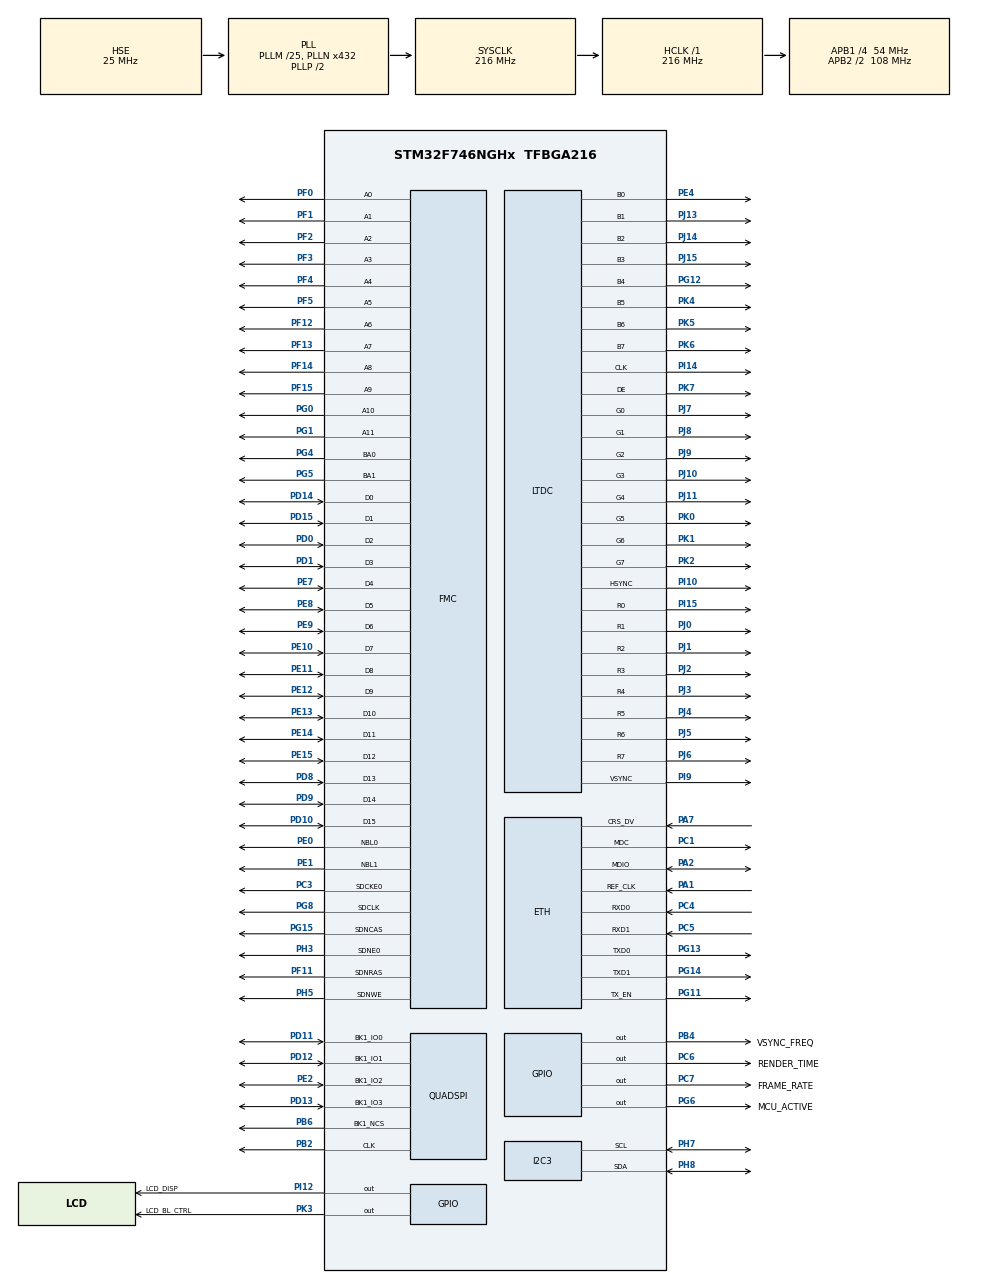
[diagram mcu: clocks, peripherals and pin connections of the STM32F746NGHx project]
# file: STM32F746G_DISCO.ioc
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CORTEX_M7.ART_ACCLERATOR_ENABLE=1
CORTEX_M7.AccessPermission-Cortex_Memory_Protection_Unit_Region0_Settings=MPU_REGION_FULL_ACCESS
CORTEX_M7.AccessPermission-Cortex_Memory_Protection_Unit_Region1_Settings=MPU_REGION_FULL_ACCESS
CORTEX_M7.BaseAddress-Cortex_Memory_Protection_Unit_Region0_Settings=0x2004C000
CORTEX_M7.BaseAddress-Cortex_Memory_Protection_Unit_Region1_Settings=0x90000000
CORTEX_M7.CPU_DCache=Enabled
CORTEX_M7.CPU_ICache=Enabled
CORTEX_M7.Enable-Cortex_Memory_Protection_Unit_Region0_Settings=MPU_REGION_ENABLE
CORTEX_M7.Enable-Cortex_Memory_Protection_Unit_Region1_Settings=MPU_REGION_ENABLE
CORTEX_M7.IsCacheable-Cortex_Memory_Protection_Unit_Region1_Settings=MPU_ACCESS_CACHEABLE
CORTEX_M7.MPU_Control=MPU_HFNMI_PRIVDEF
CORTEX_M7.PREFETCH_ENABLE=1
CORTEX_M7.Size-Cortex_Memory_Protection_Unit_Region0_Settings=MPU_REGION_SIZE_16KB
CORTEX_M7.Size-Cortex_Memory_Protection_Unit_Region1_Settings=MPU_REGION_SIZE_16MB
CORTEX_M7.TypeExtField-Cortex_Memory_Protection_Unit_Region0_Settings=MPU_TEX_LEVEL1
ETH.MediaInterface=HAL_ETH_RMII_MODE
FMC.CASLatency1=FMC_SDRAM_CAS_LATENCY_3
FMC.ExitSelfRefreshDelay1=7
FMC.LoadToActiveDelay1=2
FMC.RCDDelay1=2
FMC.RPDelay1=2
FMC.ReadBurst1=FMC_SDRAM_RBURST_ENABLE
FMC.RowCycleDelay1=7
FMC.SDClockPeriod1=FMC_SDRAM_CLOCK_PERIOD_2
FMC.SelfRefreshTime1=4
FMC.WriteRecoveryTime1=3
FREERTOS.Tasks01=defaultTask,24,1024,StartDefaultTask,Default,NULL,Dynamic,NULL,NULL;TouchGFXTask,24,4096,TouchGFX_Task,As external,NULL,Dynamic,NULL,NULL;videoTask,8,1000,videoTaskFunc,As external,NULL,Dynamic,NULL,NULL;llrpTask,24,1024,StartLlrpTask,As external,NULL,Dynamic,NULL,NULL
FREERTOS.configTOTAL_HEAP_SIZE=65536
FREERTOS.configUSE_APPLICATION_TASK_TAG=1
FREERTOS.configUSE_IDLE_HOOK=1
I2C3.Timing=0x20404768
LIBJPEG.RGB_ORDERING=BGR
LTDC.ActiveH=272
LTDC.ActiveW=480
LTDC.Alpha_L0=255
LTDC.FBStartAdress_L0=0xC0000000
LTDC.HBP=13
LTDC.HFP=32
LTDC.HSync=41
LTDC.ImageHeight_L0=272
LTDC.ImageWidth_L0=480
LTDC.Layers=0
LTDC.PixelFormat_L0=LTDC_PIXEL_FORMAT_RGB565
LTDC.VSync=10
LTDC.WindowX1_L0=480
LTDC.WindowY1_L0=272
LWIP.BSP.number=1
LWIP.GATEWAY_ADDRESS=000.000.000.000
LWIP.IP_ADDRESS=169.254.001.002
LWIP.LWIP_DHCP=0
LWIP.NETMASK_ADDRESS=255.255.000.000
LWIP.Version=v2.1.2_Cube
LWIP0.BSP.STBoard=false
LWIP0.BSP.api=BSP_COMPONENT_DRIVER
LWIP0.BSP.component=LAN8742
LWIP0.BSP.instance=LAN8742
LWIP0.BSP.name=Driver_PHY
LWIP0.BSP.semaphore=S_LAN8742
LWIP0.BSP.solution=LAN8742
Mcu.Family=STM32F7
Mcu.Name=STM32F746NGHx
Mcu.Package=TFBGA216
NVIC.DMA2D_IRQn=true\:5\:0\:true\:false\:true\:true\:true\:true\:true
NVIC.ETH_IRQn=true\:5\:0\:false\:false\:true\:true\:false\:true\:true
NVIC.LTDC_IRQn=true\:5\:0\:true\:false\:true\:true\:true\:true\:true
NVIC.PriorityGroup=NVIC_PRIORITYGROUP_4
NVIC.TIM6_DAC_IRQn=true\:0\:0\:false\:false\:true\:false\:false\:true\:true
NVIC.TimeBase=TIM6_DAC_IRQn
NVIC.TimeBaseIP=TIM6
PA1.Mode=RMII
PA1.Signal=ETH_REF_CLK
PA13.Mode=Serial_Wire
PA13.Signal=SYS_JTMS-SWDIO
PA14.Mode=Serial_Wire
PA14.Signal=SYS_JTCK-SWCLK
PA2.Mode=RMII
PA2.Signal=ETH_MDIO
PA7.Mode=RMII
PA7.Signal=ETH_CRS_DV
PB2.Mode=Single Bank 1
PB2.Signal=QUADSPI_CLK
PB4.GPIO_Label=VSYNC_FREQ
PB4.GPIO_Speed=GPIO_SPEED_FREQ_VERY_HIGH
PB4.Signal=GPIO_Output
PB6.Mode=Single Bank 1
PB6.Signal=QUADSPI_BK1_NCS
PC1.Mode=RMII
PC1.Signal=ETH_MDC
PC3.Mode=SdramChipSelect1_1
PC3.Signal=FMC_SDCKE0
PC4.Mode=RMII
PC4.Signal=ETH_RXD0
PC5.Mode=RMII
PC5.Signal=ETH_RXD1
PC6.GPIO_Label=RENDER_TIME
PC6.GPIO_Speed=GPIO_SPEED_FREQ_VERY_HIGH
PC6.Signal=GPIO_Output
PC7.GPIO_Label=FRAME_RATE
PC7.GPIO_Speed=GPIO_SPEED_FREQ_VERY_HIGH
PC7.Signal=GPIO_Output
PD0.Signal=FMC_D2_DA2
PD1.Signal=FMC_D3_DA3
PD10.Signal=FMC_D15_DA15
PD11.Mode=Single Bank 1
PD11.Signal=QUADSPI_BK1_IO0
PD12.Mode=Single Bank 1
PD12.Signal=QUADSPI_BK1_IO1
PD13.Mode=Single Bank 1
PD13.Signal=QUADSPI_BK1_IO3
PD14.Signal=FMC_D0_DA0
PD15.Signal=FMC_D1_DA1
PD8.Signal=FMC_D13_DA13
PD9.Signal=FMC_D14_DA14
PE0.Signal=FMC_NBL0
PE1.Signal=FMC_NBL1
PE10.Signal=FMC_D7_DA7
PE11.Signal=FMC_D8_DA8
PE12.Signal=FMC_D9_DA9
PE13.Signal=FMC_D10_DA10
PE14.Signal=FMC_D11_DA11
PE15.Signal=FMC_D12_DA12
PE2.Mode=Single Bank 1
PE2.Signal=QUADSPI_BK1_IO2
PE4.Mode=RGB888
PE4.Signal=LTDC_B0
PE7.Signal=FMC_D4_DA4
PE8.Signal=FMC_D5_DA5
PE9.Signal=FMC_D6_DA6
PF0.Signal=FMC_A0
PF1.Signal=FMC_A1
PF11.Signal=FMC_SDNRAS
PF12.Signal=FMC_A6
PF13.Signal=FMC_A7
PF14.Signal=FMC_A8
PF15.Signal=FMC_A9
PF2.Signal=FMC_A2
PF3.Signal=FMC_A3
PF4.Signal=FMC_A4
PF5.Signal=FMC_A5
PG0.Signal=FMC_A10
PG1.Signal=FMC_A11
PG11.Mode=RMII
PG11.Signal=ETH_TX_EN
PG12.Mode=RGB888
PG12.Signal=LTDC_B4
PG13.Mode=RMII
PG13.Signal=ETH_TXD0
PG14.Mode=RMII
PG14.Signal=ETH_TXD1
PG15.Signal=FMC_SDNCAS
PG4.Signal=FMC_A14_BA0
PG5.Signal=FMC_A15_BA1
PG6.GPIO_Label=MCU_ACTIVE
PG6.GPIO_Speed=GPIO_SPEED_FREQ_VERY_HIGH
PG6.Signal=GPIO_Output
PG8.Signal=FMC_SDCLK
PH0/OSC_IN.Mode=HSE-External-Oscillator
PH0/OSC_IN.Signal=RCC_OSC_IN
PH1/OSC_OUT.Mode=HSE-External-Oscillator
PH1/OSC_OUT.Signal=RCC_OSC_OUT
PH3.Mode=SdramChipSelect1_1
PH3.Signal=FMC_SDNE0
PH5.Signal=FMC_SDNWE
PH7.GPIO_Pu=GPIO_PULLUP
PH7.Mode=I2C
PH7.Signal=I2C3_SCL
PH8.GPIO_Pu=GPIO_PULLUP
PH8.Mode=I2C
PH8.Signal=I2C3_SDA
PI10.Mode=RGB888
PI10.Signal=LTDC_HSYNC
PI12.GPIO_Label=LCD_DISP
PI12.PinState=GPIO_PIN_SET
PI12.Signal=GPIO_Output
PI14.Mode=RGB888
PI14.Signal=LTDC_CLK
PI15.Mode=RGB888
PI15.Signal=LTDC_R0
PI9.Mode=RGB888
PI9.Signal=LTDC_VSYNC
PJ0.Mode=RGB888
PJ0.Signal=LTDC_R1
PJ1.Mode=RGB888
PJ1.Signal=LTDC_R2
PJ10.Mode=RGB888
PJ10.Signal=LTDC_G3
PJ11.Mode=RGB888
PJ11.Signal=LTDC_G4
PJ13.Mode=RGB888
PJ13.Signal=LTDC_B1
PJ14.Mode=RGB888
PJ14.Signal=LTDC_B2
PJ15.Mode=RGB888
PJ15.Signal=LTDC_B3
PJ2.Mode=RGB888
PJ2.Signal=LTDC_R3
PJ3.Mode=RGB888
PJ3.Signal=LTDC_R4
PJ4.Mode=RGB888
PJ4.Signal=LTDC_R5
PJ5.Mode=RGB888
PJ5.Signal=LTDC_R6
PJ6.Mode=RGB888
PJ6.Signal=LTDC_R7
PJ7.Mode=RGB888
PJ7.Signal=LTDC_G0
PJ8.Mode=RGB888
PJ8.Signal=LTDC_G1
PJ9.Mode=RGB888
PJ9.Signal=LTDC_G2
PK0.Mode=RGB888
PK0.Signal=LTDC_G5
PK1.Mode=RGB888
PK1.Signal=LTDC_G6
PK2.Mode=RGB888
PK2.Signal=LTDC_G7
PK3.GPIO_Label=LCD_BL_CTRL
PK3.PinState=GPIO_PIN_SET
PK3.Signal=GPIO_Output
PK4.Mode=RGB888
PK4.Signal=LTDC_B5
PK5.Mode=RGB888
PK5.Signal=LTDC_B6
PK6.Mode=RGB888
PK6.Signal=LTDC_B7
PK7.Mode=RGB888
PK7.Signal=LTDC_DE
ProjectManager.HeapSize=0xA00
ProjectManager.StackSize=0xA00
ProjectManager.TargetToolchain=STM32CubeIDE
QUADSPI.ChipSelectHighTime=QSPI_CS_HIGH_TIME_6_CYCLE
QUADSPI.ClockPrescaler=1
QUADSPI.FifoThreshold=4
QUADSPI.FlashSize=24
QUADSPI.SampleShifting=QSPI_SAMPLE_SHIFTING_HALFCYCLE
RCC.AHBFreq_Value=216000000
RCC.APB1CLKDivider=RCC_HCLK_DIV4
RCC.APB1Freq_Value=54000000
RCC.APB1TimFreq_Value=108000000
RCC.APB2CLKDivider=RCC_HCLK_DIV2
RCC.APB2Freq_Value=108000000
RCC.APB2TimFreq_Value=216000000
RCC.CortexFreq_Value=216000000
RCC.HCLKFreq_Value=216000000
RCC.HSE_VALUE=25000000
RCC.HSI_VALUE=16000000
RCC.LSE_VALUE=32768
RCC.PLLI2SN=100
RCC.PLLM=25
RCC.PLLN=432
RCC.PLLSAIN=384
RCC.PLLSAIR=5
RCC.PLLSAIRDiv=RCC_PLLSAIDIVR_8
RCC.PLLSourceVirtual=RCC_PLLSOURCE_HSE
RCC.SYSCLKFreq_VALUE=216000000
RCC.SYSCLKSource=RCC_SYSCLKSOURCE_PLLCLK
RCC.USBFreq_Value=216000000
RCC.VCOOutputFreq_Value=432000000
SH.FMC_A0.0=FMC_A0,12b-sda1
SH.FMC_A1.0=FMC_A1,12b-sda1
SH.FMC_A10.0=FMC_A10,12b-sda1
SH.FMC_A11.0=FMC_A11,12b-sda1
SH.FMC_A14_BA0.0=FMC_BA0,FourSdramBanks1
SH.FMC_A15_BA1.0=FMC_BA1,FourSdramBanks1
SH.FMC_A2.0=FMC_A2,12b-sda1
SH.FMC_A3.0=FMC_A3,12b-sda1
SH.FMC_A4.0=FMC_A4,12b-sda1
SH.FMC_A5.0=FMC_A5,12b-sda1
SH.FMC_A6.0=FMC_A6,12b-sda1
SH.FMC_A7.0=FMC_A7,12b-sda1
SH.FMC_A8.0=FMC_A8,12b-sda1
SH.FMC_A9.0=FMC_A9,12b-sda1
SH.FMC_D0_DA0.0=FMC_D0,sd-16b-d1
SH.FMC_D10_DA10.0=FMC_D10,sd-16b-d1
SH.FMC_D11_DA11.0=FMC_D11,sd-16b-d1
SH.FMC_D12_DA12.0=FMC_D12,sd-16b-d1
SH.FMC_D13_DA13.0=FMC_D13,sd-16b-d1
SH.FMC_D14_DA14.0=FMC_D14,sd-16b-d1
SH.FMC_D15_DA15.0=FMC_D15,sd-16b-d1
SH.FMC_D1_DA1.0=FMC_D1,sd-16b-d1
SH.FMC_D2_DA2.0=FMC_D2,sd-16b-d1
SH.FMC_D3_DA3.0=FMC_D3,sd-16b-d1
SH.FMC_D4_DA4.0=FMC_D4,sd-16b-d1
SH.FMC_D5_DA5.0=FMC_D5,sd-16b-d1
SH.FMC_D6_DA6.0=FMC_D6,sd-16b-d1
SH.FMC_D7_DA7.0=FMC_D7,sd-16b-d1
SH.FMC_D8_DA8.0=FMC_D8,sd-16b-d1
SH.FMC_D9_DA9.0=FMC_D9,sd-16b-d1
SH.FMC_NBL0.0=FMC_NBL0,Sd2ByteEnable1
SH.FMC_NBL1.0=FMC_NBL1,Sd2ByteEnable1
SH.FMC_SDCLK.0=FMC_SDCLK,12b-sda1
SH.FMC_SDNCAS.0=FMC_SDNCAS,12b-sda1
SH.FMC_SDNRAS.0=FMC_SDNRAS,12b-sda1
SH.FMC_SDNWE.0=FMC_SDNWE,12b-sda1
STMicroelectronics.X-CUBE-TOUCHGFX.4.26.0.ApplicationCcGraphicsJjApplication=TouchGFXOoGenerator
STMicroelectronics.X-CUBE-TOUCHGFX.4.26.0.tgfx_address1=0xC0000000
STMicroelectronics.X-CUBE-TOUCHGFX.4.26.0.tgfx_address2=0xC003FC00
STMicroelectronics.X-CUBE-TOUCHGFX.4.26.0.tgfx_buffering_strategy=Double
STMicroelectronics.X-CUBE-TOUCHGFX.4.26.0.tgfx_display_interface=disp_ltdc
STMicroelectronics.X-CUBE-TOUCHGFX.4.26.0.tgfx_hardware_accelerator=dma_2d
STMicroelectronics.X-CUBE-TOUCHGFX.4.26.0.tgfx_location=Allocate
STMicroelectronics.X-CUBE-TOUCHGFX.4.26.0.tgfx_vector_fonts=Enabled
STMicroelectronics.X-CUBE-TOUCHGFX.4.26.0.tgfx_vector_rendering=Software
STMicroelectronics.X-CUBE-TOUCHGFX.4.26.0.tgfx_video=Software
STMicroelectronics.X-CUBE-TOUCHGFX.4.26.0.tgfx_video_buffer_format=RGB565\:2
STMicroelectronics.X-CUBE-TOUCHGFX.4.26.0.tgfx_video_height=272
STMicroelectronics.X-CUBE-TOUCHGFX.4.26.0.tgfx_video_strategy=2
STMicroelectronics.X-CUBE-TOUCHGFX.4.26.0.tgfx_video_width=480
STMicroelectronics.X-CUBE-TOUCHGFX.4.26.0.tgfx_vsync=vsync_ltdc
VP_CRC_VS_CRC.Mode=CRC_Activate
VP_DMA2D_VS_DMA2D.Mode=DMA2D_Activate
VP_FREERTOS_VS_CMSIS_V2.Mode=CMSIS_V2
VP_LIBJPEG_VS_JPEGLIB.Mode=Enabled
VP_LWIP_VS_Enabled.Mode=Enabled
VP_STMicroelectronics.X-CUBE-TOUCHGFX_VS_GraphicsJjApplication_4.26.0.Mode=GraphicsJjApplication
VP_SYS_VS_tim6.Mode=TIM6
board=custom

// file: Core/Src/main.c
/* USER CODE BEGIN Header */
/**
 ******************************************************************************
 * @file           : main.c
 * @brief          : Main program body
 ******************************************************************************
 * @attention
 *
 * <h2><center>&copy; Copyright (c) 2020 STMicroelectronics.
 * All rights reserved.</center></h2>
 *
 * This software component is licensed by ST under Ultimate Liberty license
 * SLA0044, the "License"; You may not use this file except in compliance with
 * the License. You may obtain a copy of the License at:
 *                             www.st.com/SLA0044
 *
 ******************************************************************************
 */
/* USER CODE END Header */
#include "main.h"
#include "app_touchgfx.h"
#include "cmsis_os.h"
#include "libjpeg.h"
#include "lwip.h"

/* USER CODE BEGIN PD */

#define REFRESH_COUNT 1835

#define SDRAM_TIMEOUT ((uint32_t)0xFFFF)
#define SDRAM_MODEREG_BURST_LENGTH_1 ((uint16_t)0x0000)
#define SDRAM_MODEREG_BURST_LENGTH_2 ((uint16_t)0x0001)
#define SDRAM_MODEREG_BURST_LENGTH_4 ((uint16_t)0x0002)
#define SDRAM_MODEREG_BURST_LENGTH_8 ((uint16_t)0x0004)
#define SDRAM_MODEREG_BURST_TYPE_SEQUENTIAL ((uint16_t)0x0000)
#define SDRAM_MODEREG_BURST_TYPE_INTERLEAVED ((uint16_t)0x0008)
#define SDRAM_MODEREG_CAS_LATENCY_2 ((uint16_t)0x0020)
#define SDRAM_MODEREG_CAS_LATENCY_3 ((uint16_t)0x0030)
#define SDRAM_MODEREG_OPERATING_MODE_STANDARD ((uint16_t)0x0000)
#define SDRAM_MODEREG_WRITEBURST_MODE_PROGRAMMED ((uint16_t)0x0000)
#define SDRAM_MODEREG_WRITEBURST_MODE_SINGLE ((uint16_t)0x0200)

#define FLASH_READ_JEDEC_ID 0x9F
#define FLASH_FAST_READ_QUAD_IO 0xEB
#define FLASH_REVC03_MANUFACTURER_ID 0xEF
#define FLASH_N25Q128A_DUMMY_CYCLES 0x0A
#define FLASH_W25Q128J_DUMMY_CYCLES 0x06

/* USER CODE END PD */

CRC_HandleTypeDef hcrc;

DMA2D_HandleTypeDef hdma2d;

I2C_HandleTypeDef hi2c3;

LTDC_HandleTypeDef hltdc;

QSPI_HandleTypeDef hqspi;

SDRAM_HandleTypeDef hsdram1;

/* Definitions for defaultTask */
osThreadId_t defaultTaskHandle;
const osThreadAttr_t defaultTask_attributes = {
    .name = "defaultTask",
    .stack_size = 1024 * 4,
    .priority = (osPriority_t)osPriorityNormal,
};
/* Definitions for TouchGFXTask */
osThreadId_t TouchGFXTaskHandle;
const osThreadAttr_t TouchGFXTask_attributes = {
    .name = "TouchGFXTask",
    .stack_size = 4096 * 4,
    .priority = (osPriority_t)osPriorityNormal,
};
/* Definitions for videoTask */
osThreadId_t videoTaskHandle;
const osThreadAttr_t videoTask_attributes = {
    .name = "videoTask",
    .stack_size = 1000 * 4,
    .priority = (osPriority_t)osPriorityLow,
};
/* Definitions for llrpTask */
osThreadId_t llrpTaskHandle;
const osThreadAttr_t llrpTask_attributes = {
    .name = "llrpTask",
    .stack_size = 1024 * 4,
    .priority = (osPriority_t)osPriorityNormal,
};
/* USER CODE BEGIN PV */
static FMC_SDRAM_CommandTypeDef Command;
/* USER CODE END PV */

void SystemClock_Config(void);
static void MPU_Config(void);
static void MX_GPIO_Init(void);
static void MX_CRC_Init(void);
static void MX_DMA2D_Init(void);
static void MX_FMC_Init(void);
static void MX_I2C3_Init(void);
static void MX_LTDC_Init(void);
static void MX_QUADSPI_Init(void);
void StartDefaultTask(void *argument);
extern void TouchGFX_Task(void *argument);
extern void videoTaskFunc(void *argument);
extern void StartLlrpTask(void *argument);

/* USER CODE BEGIN PFP */
void GetManufacturerId(uint8_t *manufacturer_id);
void EnableMemoryMappedMode(uint8_t manufacturer_id);
extern void StartLlrpTask(void *argument);
/* USER CODE END PFP */

int main(void) {

  /* MPU Configuration--------------------------------------------------------*/
  MPU_Config();

  /* Enable the CPU Cache */

  /* Enable I-Cache---------------------------------------------------------*/
  SCB_EnableICache();

  /* Enable D-Cache---------------------------------------------------------*/
  SCB_EnableDCache();

  /* MCU Configuration--------------------------------------------------------*/

  /* Reset of all peripherals, Initializes the Flash interface and the Systick.
   */
  HAL_Init();

  /* Configure the system clock */
  SystemClock_Config();

  /* Initialize all configured peripherals */
  MX_GPIO_Init();
  MX_CRC_Init();
  MX_DMA2D_Init();
  MX_FMC_Init();
  MX_I2C3_Init();
  MX_LTDC_Init();
  MX_QUADSPI_Init();
  MX_LIBJPEG_Init();
  MX_TouchGFX_Init();
  /* Call PreOsInit function */
  MX_TouchGFX_PreOSInit();

  /* Init scheduler */
  osKernelInitialize();

  /* Create the thread(s) */
  /* creation of defaultTask */
  defaultTaskHandle =
      osThreadNew(StartDefaultTask, NULL, &defaultTask_attributes);

  /* creation of TouchGFXTask */
  TouchGFXTaskHandle =
      osThreadNew(TouchGFX_Task, NULL, &TouchGFXTask_attributes);

  /* creation of videoTask */
  videoTaskHandle = osThreadNew(videoTaskFunc, NULL, &videoTask_attributes);

  /* creation of llrpTask */
  llrpTaskHandle = osThreadNew(StartLlrpTask, NULL, &llrpTask_attributes);

  /* Start scheduler */
  osKernelStart();

  /* We should never get here as control is now taken by the scheduler */

  /* Infinite loop */
  while (1) {

  }
}

void SystemClock_Config(void) {
  RCC_OscInitTypeDef RCC_OscInitStruct = {0};
  RCC_ClkInitTypeDef RCC_ClkInitStruct = {0};

  /** Configure the main internal regulator output voltage
   */
  __HAL_RCC_PWR_CLK_ENABLE();
  __HAL_PWR_VOLTAGESCALING_CONFIG(PWR_REGULATOR_VOLTAGE_SCALE1);

  /** Initializes the RCC Oscillators according to the specified parameters
   * in the RCC_OscInitTypeDef structure.
   */
  RCC_OscInitStruct.OscillatorType = RCC_OSCILLATORTYPE_HSE;
  RCC_OscInitStruct.HSEState = RCC_HSE_ON;
  RCC_OscInitStruct.PLL.PLLState = RCC_PLL_ON;
  RCC_OscInitStruct.PLL.PLLSource = RCC_PLLSOURCE_HSE;
  RCC_OscInitStruct.PLL.PLLM = 25;
  RCC_OscInitStruct.PLL.PLLN = 432;
  RCC_OscInitStruct.PLL.PLLP = RCC_PLLP_DIV2;
  RCC_OscInitStruct.PLL.PLLQ = 2;
  if (HAL_RCC_OscConfig(&RCC_OscInitStruct) != HAL_OK) {
    Error_Handler();
  }

  /** Activate the Over-Drive mode
   */
  if (HAL_PWREx_EnableOverDrive() != HAL_OK) {
    Error_Handler();
  }

  /** Initializes the CPU, AHB and APB buses clocks
   */
  RCC_ClkInitStruct.ClockType = RCC_CLOCKTYPE_HCLK | RCC_CLOCKTYPE_SYSCLK |
                                RCC_CLOCKTYPE_PCLK1 | RCC_CLOCKTYPE_PCLK2;
  RCC_ClkInitStruct.SYSCLKSource = RCC_SYSCLKSOURCE_PLLCLK;
  RCC_ClkInitStruct.AHBCLKDivider = RCC_SYSCLK_DIV1;
  RCC_ClkInitStruct.APB1CLKDivider = RCC_HCLK_DIV4;
  RCC_ClkInitStruct.APB2CLKDivider = RCC_HCLK_DIV2;

  if (HAL_RCC_ClockConfig(&RCC_ClkInitStruct, FLASH_LATENCY_7) != HAL_OK) {
    Error_Handler();
  }
}

static void MX_CRC_Init(void) {

  hcrc.Instance = CRC;
  hcrc.Init.DefaultPolynomialUse = DEFAULT_POLYNOMIAL_ENABLE;
  hcrc.Init.DefaultInitValueUse = DEFAULT_INIT_VALUE_ENABLE;
  hcrc.Init.InputDataInversionMode = CRC_INPUTDATA_INVERSION_NONE;
  hcrc.Init.OutputDataInversionMode = CRC_OUTPUTDATA_INVERSION_DISABLE;
  hcrc.InputDataFormat = CRC_INPUTDATA_FORMAT_BYTES;
  if (HAL_CRC_Init(&hcrc) != HAL_OK) {
    Error_Handler();
  }
}

static void MX_DMA2D_Init(void) {

  hdma2d.Instance = DMA2D;
  hdma2d.Init.Mode = DMA2D_M2M;
  hdma2d.Init.ColorMode = DMA2D_OUTPUT_ARGB8888;
  hdma2d.Init.OutputOffset = 0;
  hdma2d.LayerCfg[1].InputOffset = 0;
  hdma2d.LayerCfg[1].InputColorMode = DMA2D_INPUT_ARGB8888;
  hdma2d.LayerCfg[1].AlphaMode = DMA2D_NO_MODIF_ALPHA;
  hdma2d.LayerCfg[1].InputAlpha = 0;
  if (HAL_DMA2D_Init(&hdma2d) != HAL_OK) {
    Error_Handler();
  }
  if (HAL_DMA2D_ConfigLayer(&hdma2d, 1) != HAL_OK) {
    Error_Handler();
  }
}

static void MX_I2C3_Init(void) {

  /* USER CODE BEGIN I2C3_Init 0 */
  HAL_Delay(100); // Delay to fix initialization issue on some boards
  /* USER CODE END I2C3_Init 0 */

  hi2c3.Instance = I2C3;
  hi2c3.Init.Timing = 0x20404768;
  hi2c3.Init.OwnAddress1 = 0;
  hi2c3.Init.AddressingMode = I2C_ADDRESSINGMODE_7BIT;
  hi2c3.Init.DualAddressMode = I2C_DUALADDRESS_DISABLE;
  hi2c3.Init.OwnAddress2 = 0;
  hi2c3.Init.OwnAddress2Masks = I2C_OA2_NOMASK;
  hi2c3.Init.GeneralCallMode = I2C_GENERALCALL_DISABLE;
  hi2c3.Init.NoStretchMode = I2C_NOSTRETCH_DISABLE;
  if (HAL_I2C_Init(&hi2c3) != HAL_OK) {
    Error_Handler();
  }

  /** Configure Analogue filter
   */
  if (HAL_I2CEx_ConfigAnalogFilter(&hi2c3, I2C_ANALOGFILTER_ENABLE) != HAL_OK) {
    Error_Handler();
  }

  /** Configure Digital filter
   */
  if (HAL_I2CEx_ConfigDigitalFilter(&hi2c3, 0) != HAL_OK) {
    Error_Handler();
  }
}

static void MX_LTDC_Init(void) {

  LTDC_LayerCfgTypeDef pLayerCfg = {0};

  hltdc.Instance = LTDC;
  hltdc.Init.HSPolarity = LTDC_HSPOLARITY_AL;
  hltdc.Init.VSPolarity = LTDC_VSPOLARITY_AL;
  hltdc.Init.DEPolarity = LTDC_DEPOLARITY_AL;
  hltdc.Init.PCPolarity = LTDC_PCPOLARITY_IPC;
  hltdc.Init.HorizontalSync = 40;
  hltdc.Init.VerticalSync = 9;
  hltdc.Init.AccumulatedHBP = 53;
  hltdc.Init.AccumulatedVBP = 11;
  hltdc.Init.AccumulatedActiveW = 533;
  hltdc.Init.AccumulatedActiveH = 283;
  hltdc.Init.TotalWidth = 565;
  hltdc.Init.TotalHeigh = 285;
  hltdc.Init.Backcolor.Blue = 0;
  hltdc.Init.Backcolor.Green = 0;
  hltdc.Init.Backcolor.Red = 0;
  if (HAL_LTDC_Init(&hltdc) != HAL_OK) {
    Error_Handler();
  }
  pLayerCfg.WindowX0 = 0;
  pLayerCfg.WindowX1 = 480;
  pLayerCfg.WindowY0 = 0;
  pLayerCfg.WindowY1 = 272;
  pLayerCfg.PixelFormat = LTDC_PIXEL_FORMAT_RGB565;
  pLayerCfg.Alpha = 255;
  pLayerCfg.Alpha0 = 0;
  pLayerCfg.BlendingFactor1 = LTDC_BLENDING_FACTOR1_CA;
  pLayerCfg.BlendingFactor2 = LTDC_BLENDING_FACTOR2_CA;
  pLayerCfg.FBStartAdress = 0xC0000000;
  pLayerCfg.ImageWidth = 480;
  pLayerCfg.ImageHeight = 272;
  pLayerCfg.Backcolor.Blue = 0;
  pLayerCfg.Backcolor.Green = 0;
  pLayerCfg.Backcolor.Red = 0;
  if (HAL_LTDC_ConfigLayer(&hltdc, &pLayerCfg, 0) != HAL_OK) {
    Error_Handler();
  }
}

static void MX_QUADSPI_Init(void) {

  /* QUADSPI parameter configuration*/
  hqspi.Instance = QUADSPI;
  hqspi.Init.ClockPrescaler = 1;
  hqspi.Init.FifoThreshold = 4;
  hqspi.Init.SampleShifting = QSPI_SAMPLE_SHIFTING_HALFCYCLE;
  hqspi.Init.FlashSize = 24;
  hqspi.Init.ChipSelectHighTime = QSPI_CS_HIGH_TIME_6_CYCLE;
  hqspi.Init.ClockMode = QSPI_CLOCK_MODE_0;
  hqspi.Init.FlashID = QSPI_FLASH_ID_1;
  hqspi.Init.DualFlash = QSPI_DUALFLASH_DISABLE;
  if (HAL_QSPI_Init(&hqspi) != HAL_OK) {
    Error_Handler();
  }
  /* USER CODE BEGIN QUADSPI_Init 2 */
  uint8_t manufacturer_id;
  GetManufacturerId(&manufacturer_id);
  EnableMemoryMappedMode(manufacturer_id);
  HAL_NVIC_DisableIRQ(QUADSPI_IRQn);
  /* USER CODE END QUADSPI_Init 2 */
}

/* FMC initialization function */
static void MX_FMC_Init(void) {

  FMC_SDRAM_TimingTypeDef SdramTiming = {0};

  /** Perform the SDRAM1 memory initialization sequence
   */
  hsdram1.Instance = FMC_SDRAM_DEVICE;
  /* hsdram1.Init */
  hsdram1.Init.SDBank = FMC_SDRAM_BANK1;
  hsdram1.Init.ColumnBitsNumber = FMC_SDRAM_COLUMN_BITS_NUM_8;
  hsdram1.Init.RowBitsNumber = FMC_SDRAM_ROW_BITS_NUM_12;
  hsdram1.Init.MemoryDataWidth = FMC_SDRAM_MEM_BUS_WIDTH_16;
  hsdram1.Init.InternalBankNumber = FMC_SDRAM_INTERN_BANKS_NUM_4;
  hsdram1.Init.CASLatency = FMC_SDRAM_CAS_LATENCY_3;
  hsdram1.Init.WriteProtection = FMC_SDRAM_WRITE_PROTECTION_DISABLE;
  hsdram1.Init.SDClockPeriod = FMC_SDRAM_CLOCK_PERIOD_2;
  hsdram1.Init.ReadBurst = FMC_SDRAM_RBURST_ENABLE;
  hsdram1.Init.ReadPipeDelay = FMC_SDRAM_RPIPE_DELAY_0;
  /* SdramTiming */
  SdramTiming.LoadToActiveDelay = 2;
  SdramTiming.ExitSelfRefreshDelay = 7;
  SdramTiming.SelfRefreshTime = 4;
  SdramTiming.RowCycleDelay = 7;
  SdramTiming.WriteRecoveryTime = 3;
  SdramTiming.RPDelay = 2;
  SdramTiming.RCDDelay = 2;

  if (HAL_SDRAM_Init(&hsdram1, &SdramTiming) != HAL_OK) {
    Error_Handler();
  }

  /* USER CODE BEGIN FMC_Init 2 */
  __IO uint32_t tmpmrd = 0;

  /* Step 1: Configure a clock configuration enable command */
  Command.CommandMode = FMC_SDRAM_CMD_CLK_ENABLE;
  Command.CommandTarget = FMC_SDRAM_CMD_TARGET_BANK1;
  Command.AutoRefreshNumber = 1;
  Command.ModeRegisterDefinition = 0;

  /* Send the command */
  HAL_SDRAM_SendCommand(&hsdram1, &Command, SDRAM_TIMEOUT);

  /* Step 2: Insert 100 us minimum delay */
  /* Inserted delay is equal to 1 ms due to systick time base unit (ms) */
  HAL_Delay(1);

  /* Step 3: Configure a PALL (precharge all) command */
  Command.CommandMode = FMC_SDRAM_CMD_PALL;
  Command.CommandTarget = FMC_SDRAM_CMD_TARGET_BANK1;
  Command.AutoRefreshNumber = 1;
  Command.ModeRegisterDefinition = 0;

  /* Send the command */
  HAL_SDRAM_SendCommand(&hsdram1, &Command, SDRAM_TIMEOUT);

  /* Step 4: Configure an Auto Refresh command */
  Command.CommandMode = FMC_SDRAM_CMD_AUTOREFRESH_MODE;
  Command.CommandTarget = FMC_SDRAM_CMD_TARGET_BANK1;
  Command.AutoRefreshNumber = 8;
  Command.ModeRegisterDefinition = 0;

  /* Send the command */
  HAL_SDRAM_SendCommand(&hsdram1, &Command, SDRAM_TIMEOUT);

  /* Step 5: Program the external memory mode register */
  tmpmrd = (uint32_t)SDRAM_MODEREG_BURST_LENGTH_1 |
           SDRAM_MODEREG_BURST_TYPE_SEQUENTIAL | SDRAM_MODEREG_CAS_LATENCY_3 |
           SDRAM_MODEREG_OPERATING_MODE_STANDARD |
           SDRAM_MODEREG_WRITEBURST_MODE_SINGLE;

  Command.CommandMode = FMC_SDRAM_CMD_LOAD_MODE;
  Command.CommandTarget = FMC_SDRAM_CMD_TARGET_BANK1;
  Command.AutoRefreshNumber = 1;
  Command.ModeRegisterDefinition = tmpmrd;

  /* Send the command */
  HAL_SDRAM_SendCommand(&hsdram1, &Command, SDRAM_TIMEOUT);

  /* Step 6: Set the refresh rate counter */
  /* Set the device refresh rate */
  HAL_SDRAM_ProgramRefreshRate(&hsdram1, REFRESH_COUNT);

  // Deactivate speculative/cache access to first FMC Bank to save FMC bandwidth
  FMC_Bank1->BTCR[0] = 0x000030D2;
  /* USER CODE END FMC_Init 2 */
}

static void MX_GPIO_Init(void) {
  GPIO_InitTypeDef GPIO_InitStruct = {0};

  /* GPIO Ports Clock Enable */
  __HAL_RCC_GPIOE_CLK_ENABLE();
  __HAL_RCC_GPIOG_CLK_ENABLE();
  __HAL_RCC_GPIOB_CLK_ENABLE();
  __HAL_RCC_GPIOA_CLK_ENABLE();
  __HAL_RCC_GPIOJ_CLK_ENABLE();
  __HAL_RCC_GPIOD_CLK_ENABLE();
  __HAL_RCC_GPIOK_CLK_ENABLE();
  __HAL_RCC_GPIOF_CLK_ENABLE();
  __HAL_RCC_GPIOI_CLK_ENABLE();
  __HAL_RCC_GPIOH_CLK_ENABLE();
  __HAL_RCC_GPIOC_CLK_ENABLE();

  /*Configure GPIO pin Output Level */
  HAL_GPIO_WritePin(VSYNC_FREQ_GPIO_Port, VSYNC_FREQ_Pin, GPIO_PIN_RESET);

  /*Configure GPIO pin Output Level */
  HAL_GPIO_WritePin(LCD_BL_CTRL_GPIO_Port, LCD_BL_CTRL_Pin, GPIO_PIN_SET);

  /*Configure GPIO pin Output Level */
  HAL_GPIO_WritePin(LCD_DISP_GPIO_Port, LCD_DISP_Pin, GPIO_PIN_SET);

  /*Configure GPIO pin Output Level */
  HAL_GPIO_WritePin(GPIOC, FRAME_RATE_Pin | RENDER_TIME_Pin, GPIO_PIN_RESET);

  /*Configure GPIO pin Output Level */
  HAL_GPIO_WritePin(MCU_ACTIVE_GPIO_Port, MCU_ACTIVE_Pin, GPIO_PIN_RESET);

  /*Configure GPIO pin : VSYNC_FREQ_Pin */
  GPIO_InitStruct.Pin = VSYNC_FREQ_Pin;
  GPIO_InitStruct.Mode = GPIO_MODE_OUTPUT_PP;
  GPIO_InitStruct.Pull = GPIO_NOPULL;
  GPIO_InitStruct.Speed = GPIO_SPEED_FREQ_VERY_HIGH;
  HAL_GPIO_Init(VSYNC_FREQ_GPIO_Port, &GPIO_InitStruct);

  /*Configure GPIO pin : LCD_BL_CTRL_Pin */
  GPIO_InitStruct.Pin = LCD_BL_CTRL_Pin;
  GPIO_InitStruct.Mode = GPIO_MODE_OUTPUT_PP;
  GPIO_InitStruct.Pull = GPIO_NOPULL;
  GPIO_InitStruct.Speed = GPIO_SPEED_FREQ_LOW;
  HAL_GPIO_Init(LCD_BL_CTRL_GPIO_Port, &GPIO_InitStruct);

  /*Configure GPIO pin : LCD_DISP_Pin */
  GPIO_InitStruct.Pin = LCD_DISP_Pin;
  GPIO_InitStruct.Mode = GPIO_MODE_OUTPUT_PP;
  GPIO_InitStruct.Pull = GPIO_NOPULL;
  GPIO_InitStruct.Speed = GPIO_SPEED_FREQ_LOW;
  HAL_GPIO_Init(LCD_DISP_GPIO_Port, &GPIO_InitStruct);

  /*Configure GPIO pins : FRAME_RATE_Pin RENDER_TIME_Pin */
  GPIO_InitStruct.Pin = FRAME_RATE_Pin | RENDER_TIME_Pin;
  GPIO_InitStruct.Mode = GPIO_MODE_OUTPUT_PP;
  GPIO_InitStruct.Pull = GPIO_NOPULL;
  GPIO_InitStruct.Speed = GPIO_SPEED_FREQ_VERY_HIGH;
  HAL_GPIO_Init(GPIOC, &GPIO_InitStruct);

  /*Configure GPIO pin : MCU_ACTIVE_Pin */
  GPIO_InitStruct.Pin = MCU_ACTIVE_Pin;
  GPIO_InitStruct.Mode = GPIO_MODE_OUTPUT_PP;
  GPIO_InitStruct.Pull = GPIO_NOPULL;
  GPIO_InitStruct.Speed = GPIO_SPEED_FREQ_VERY_HIGH;
  HAL_GPIO_Init(MCU_ACTIVE_GPIO_Port, &GPIO_InitStruct);

}

/* USER CODE BEGIN 4 */

// Read manufacturer ID of external QSPI flash
void GetManufacturerId(uint8_t *manufacturer_id) {
  QSPI_CommandTypeDef s_command_id;

  /* Initialize the read flag status register command */
  s_command_id.InstructionMode = QSPI_INSTRUCTION_1_LINE;
  s_command_id.Instruction = FLASH_READ_JEDEC_ID;
  s_command_id.AddressMode = QSPI_ADDRESS_NONE;
  s_command_id.AlternateByteMode = QSPI_ALTERNATE_BYTES_NONE;
  s_command_id.DataMode = QSPI_DATA_1_LINE;
  s_command_id.DummyCycles = 0;
  s_command_id.NbData = 1;
  s_command_id.DdrMode = QSPI_DDR_MODE_DISABLE;
  s_command_id.DdrHoldHalfCycle = QSPI_DDR_HHC_ANALOG_DELAY;
  s_command_id.SIOOMode = QSPI_SIOO_INST_EVERY_CMD;

  /* Configure the command */
  if (HAL_QSPI_Command(&hqspi, &s_command_id, HAL_QPSI_TIMEOUT_DEFAULT_VALUE) !=
      HAL_OK) {
    Error_Handler();
  }

  /* Reception of the data */
  if (HAL_QSPI_Receive(&hqspi, manufacturer_id,
                       HAL_QPSI_TIMEOUT_DEFAULT_VALUE) != HAL_OK) {
    Error_Handler();
  }
}

// Enable memory mapped mode for external QSPI flash
void EnableMemoryMappedMode(uint8_t manufacturer_id) {
  QSPI_CommandTypeDef s_command;
  QSPI_MemoryMappedTypeDef s_mem_mapped_cfg;

  /* Configure the command for the read instruction */
  s_command.InstructionMode = QSPI_INSTRUCTION_1_LINE;
  s_command.Instruction = FLASH_FAST_READ_QUAD_IO;
  s_command.AddressMode = QSPI_ADDRESS_4_LINES;
  s_command.AddressSize = QSPI_ADDRESS_24_BITS;
  s_command.AlternateByteMode = QSPI_ALTERNATE_BYTES_NONE;
  s_command.DataMode = QSPI_DATA_4_LINES;

  // Set dummy cycles according to manufacturer ID
  s_command.DummyCycles = manufacturer_id == FLASH_REVC03_MANUFACTURER_ID
                              ? FLASH_W25Q128J_DUMMY_CYCLES
                              : FLASH_N25Q128A_DUMMY_CYCLES;

  s_command.DdrMode = QSPI_DDR_MODE_DISABLE;
  s_command.DdrHoldHalfCycle = QSPI_DDR_HHC_ANALOG_DELAY;
  s_command.SIOOMode = QSPI_SIOO_INST_EVERY_CMD;

  /* Configure the memory mapped mode */
  s_mem_mapped_cfg.TimeOutActivation = QSPI_TIMEOUT_COUNTER_DISABLE;
  s_mem_mapped_cfg.TimeOutPeriod = 0;

  if (HAL_QSPI_MemoryMapped(&hqspi, &s_command, &s_mem_mapped_cfg) != HAL_OK) {
    Error_Handler();
  }
}

/* USER CODE END 4 */

/* USER CODE BEGIN Header_StartDefaultTask */
/**
 * @brief  Function implementing the defaultTask thread.
 * @param  argument: Not used
 * @retval None
 */
extern struct netif gnetif; // LwIP'nin global ağ yapısı
/* USER CODE END Header_StartDefaultTask */
void StartDefaultTask(void *argument) {
  /* init code for LWIP */
  MX_LWIP_Init();
  /* USER CODE BEGIN 5 */
  for (;;) {
    // Live Expressions sekmesinden gnetif.ip_addr.addr değerini izleyin.
    // Eğer statik IP verdiyseniz (192.168.1.101), hex karşılığı 0x6501A8C0
    // olmalıdır.

    if (gnetif.ip_addr.addr != 0) {
      // Buraya bir breakpoint (duraklatma noktası) koyarak kodun buraya
      // ulaşıp ulaşmadığını test edebilirsiniz.
      __NOP();
    }

    osDelay(1000);
  }
  /* USER CODE END 5 */
}

/* MPU Configuration */

void MPU_Config(void) {
  MPU_Region_InitTypeDef MPU_InitStruct = {0};

  /* Disables the MPU */
  HAL_MPU_Disable();

  /*
   * Region 0: Ethernet DMA Descriptors (TX + RX) @ 0x2004C000, 16KB
   * TEX=1, C=0, B=0 => Normal memory, Non-cacheable, Non-bufferable
   * Bu bolge DMA dogrudan erisir, cache ile conflict olmamali.
   */
  MPU_InitStruct.Enable = MPU_REGION_ENABLE;
  MPU_InitStruct.Number = MPU_REGION_NUMBER0;
  MPU_InitStruct.BaseAddress = 0x2004C000;
  MPU_InitStruct.Size = MPU_REGION_SIZE_16KB;
  MPU_InitStruct.SubRegionDisable = 0x0;
  MPU_InitStruct.TypeExtField = MPU_TEX_LEVEL1;
  MPU_InitStruct.AccessPermission = MPU_REGION_FULL_ACCESS;
  MPU_InitStruct.DisableExec = MPU_INSTRUCTION_ACCESS_ENABLE;
  MPU_InitStruct.IsShareable = MPU_ACCESS_NOT_SHAREABLE;
  MPU_InitStruct.IsCacheable = MPU_ACCESS_NOT_CACHEABLE;
  MPU_InitStruct.IsBufferable = MPU_ACCESS_NOT_BUFFERABLE;

  HAL_MPU_ConfigRegion(&MPU_InitStruct);

  /*
   * Region 1: LwIP Heap + RX Pool SRAM bolgesi @ 0x20048000, 32KB
   * LWIP_RAM_HEAP_POINTER = 0x20048000, RX_POOL ve heap burada.
   * TEX=1, C=0, B=0 => Normal memory, Non-cacheable
   * DCache ile Ethernet DMA RX buffer coherency sorunu bu bolgeden geliyor.
   */
  MPU_InitStruct.Number = MPU_REGION_NUMBER1;
  MPU_InitStruct.BaseAddress = 0x20048000;
  MPU_InitStruct.Size = MPU_REGION_SIZE_32KB;
  MPU_InitStruct.TypeExtField = MPU_TEX_LEVEL1;
  MPU_InitStruct.IsCacheable = MPU_ACCESS_NOT_CACHEABLE;
  MPU_InitStruct.IsBufferable = MPU_ACCESS_NOT_BUFFERABLE;
  MPU_InitStruct.IsShareable = MPU_ACCESS_NOT_SHAREABLE;

  HAL_MPU_ConfigRegion(&MPU_InitStruct);

  /*
   * Region 2: QSPI Flash @ 0x90000000, 16MB
   * TEX=0, C=1, B=0 => Normal memory, Write-Through, cacheable
   */
  MPU_InitStruct.Number = MPU_REGION_NUMBER2;
  MPU_InitStruct.BaseAddress = 0x90000000;
  MPU_InitStruct.Size = MPU_REGION_SIZE_16MB;
  MPU_InitStruct.TypeExtField = MPU_TEX_LEVEL0;
  MPU_InitStruct.IsCacheable = MPU_ACCESS_CACHEABLE;
  MPU_InitStruct.IsBufferable = MPU_ACCESS_NOT_BUFFERABLE;
  MPU_InitStruct.IsShareable = MPU_ACCESS_NOT_SHAREABLE;

  HAL_MPU_ConfigRegion(&MPU_InitStruct);

  /* Enables the MPU */
  HAL_MPU_Enable(MPU_HFNMI_PRIVDEF);
}

void HAL_TIM_PeriodElapsedCallback(TIM_HandleTypeDef *htim) {
  if (htim->Instance == TIM6) {
    HAL_IncTick();
  }
}

void Error_Handler(void) {
}
#ifdef USE_FULL_ASSERT
/**
 * @brief  Reports the name of the source file and the source line number
 *         where the assert_param error has occurred.
 * @param  file: pointer to the source file name
 * @param  line: assert_param error line source number
 * @retval None
 */
void assert_failed(uint8_t *file, uint32_t line) {
  /* USER CODE BEGIN 6 */
  /* User can add his own implementation to report the file name and line
     number, tex: printf("Wrong parameters value: file %s on line %d\r\n", file,
     line) */
  /* USER CODE END 6 */
}
#endif /* USE_FULL_ASSERT */

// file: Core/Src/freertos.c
/* USER CODE BEGIN Header */
/**
 ******************************************************************************
 * @file           : freertos.c
 * @brief          : Impinj R420 LLRP minimal EPC inventory (STM32F746G)
 *
 * Değişiklikler (analiz raporuna göre):
 *  1. DELETE_ROSPEC (ID=0) eklendi — yeniden bağlanmada eski ROSpec temizlenir
 *  2. ROReportSpec eklendi — reader'a "ROSpec bitince rapor gönder" söylenir
 *  3. ADD_ROSPEC frame 62 → 75 byte oldu (ROReportSpec +
 * TagReportContentSelector)
 *  4. LLRP_PARAM_ROREPORTSPEC / TAGREPORTCONTENTSELECTOR define'ları eklendi
 *  5. parse_tag_report_data: bilinmeyen TV tipi sz==0 olduğunda güvenli çıkış
 ******************************************************************************
 */
/* USER CODE END Header */

#include "FreeRTOS.h"
#include "cmsis_os.h"
#include "lwip/inet.h"
#include "lwip/sockets.h"
#include "main.h"
#include "task.h"
#include <stdint.h>
#include <stdio.h>
#include <string.h>

/* -------------------------------------------------------------------------- */
/*                                 AYARLAR                                    */
/* -------------------------------------------------------------------------- */

#define READER_IP_ADDR "169.254.1.1"
#define READER_PORT 5084

#define RX_BUF_SIZE 4096
#define LLRP_HEADER_LEN 10

#define SOCKET_TIMEOUT_MS 10000
#define LISTEN_TIMEOUT_MS 2000 /* Ana döngü: CMD_STOP kontrolü için kısa */

/* Komut sabitleri (View butonlarından) */
#define LLRP_CMD_CONNECT 1u
#define LLRP_CMD_START 2u
#define LLRP_CMD_STOP 3u

/* -------------------------------------------------------------------------- */
/*                          MESSAGE TYPE SABİTLERİ                            */
/* -------------------------------------------------------------------------- */

#define LLRP_MSG_ADD_ROSPEC 20
#define LLRP_MSG_ADD_ROSPEC_RESPONSE 30
#define LLRP_MSG_DELETE_ROSPEC 21          /* YENİ: yeniden bağlanma için */
#define LLRP_MSG_DELETE_ROSPEC_RESPONSE 31 /* YENİ */
#define LLRP_MSG_START_ROSPEC 22
#define LLRP_MSG_START_ROSPEC_RESPONSE 32
#define LLRP_MSG_ENABLE_ROSPEC 24
#define LLRP_MSG_ENABLE_ROSPEC_RESPONSE 34
#define LLRP_MSG_RO_ACCESS_REPORT 61
#define LLRP_MSG_KEEPALIVE 62
#define LLRP_MSG_KEEPALIVE_ACK 72
#define LLRP_MSG_READER_EVENT_NOTIFICATION 63
#define LLRP_MSG_SET_READER_CONFIG 9
#define LLRP_MSG_SET_READER_CONFIG_RESPONSE 19
#define LLRP_MSG_ERROR_MESSAGE 100

/* -------------------------------------------------------------------------- */
/*                         PARAMETER TYPE SABİTLERİ                           */
/* -------------------------------------------------------------------------- */

#define LLRP_PARAM_ROSPEC 177
#define LLRP_PARAM_ROBOUNDARYSPEC 178
#define LLRP_PARAM_ROSPECSTARTTRIGGER 179
#define LLRP_PARAM_ROSPECSTOPTRIGGER 182
#define LLRP_PARAM_AISPEC 183
#define LLRP_PARAM_AISPECSTOPTRIGGER 184
#define LLRP_PARAM_INVENTORYPARAMETERSPEC 186
#define LLRP_PARAM_ROREPORTSPEC 237 /* YENİ: rapor tetikleyicisi */
#define LLRP_PARAM_TAGREPORTCONTENTSELECTOR                                    \
  238 /* YENİ: ROReportSpec içinde zorunlu */
#define LLRP_PARAM_TAGREPORTDATA 240
#define LLRP_PARAM_EPCDATA 241
#define LLRP_PARAM_LLRPSTATUS 287

/* TV parametreler (typeNum < 128) */
#define LLRP_TV_EPC_96 13

/* -------------------------------------------------------------------------- */
/*                                 VERİ TİPLERİ                               */
/* -------------------------------------------------------------------------- */

/* EpcData: 64 byte (Model.cpp tanımıyla aynı layout olmalı) */
typedef struct {
  char hexString[60];
  uint8_t antennaId;   /* 1 veya 2 */
  int8_t peakRssi;     /* YENI: Anten rssi gucu */
  uint16_t phaseAngle; /* YENI: Faz acisi */
} EpcData;

typedef struct {
  char text[64];
} StatusMsg;

osMessageQueueId_t epcQueueHandle;
osMessageQueueId_t statusQueueHandle;
osMessageQueueId_t cmdQueueHandle;

static uint8_t rx_global[RX_BUF_SIZE];
static uint32_t g_msg_id = 1;
static int g_recv_timeout_ms = SOCKET_TIMEOUT_MS;

/* -------------------------------------------------------------------------- */
/*                            YARDIMCI MAKROLAR                               */
/* -------------------------------------------------------------------------- */

#define WRITE_U8(buf, val) (*(buf) = (uint8_t)(val))

#define WRITE_U16_BE(buf, val)                                                 \
  do {                                                                         \
    (buf)[0] = (uint8_t)(((val) >> 8) & 0xFF);                                 \
    (buf)[1] = (uint8_t)((val) & 0xFF);                                        \
  } while (0)

#define WRITE_U32_BE(buf, val)                                                 \
  do {                                                                         \
    (buf)[0] = (uint8_t)(((val) >> 24) & 0xFF);                                \
    (buf)[1] = (uint8_t)(((val) >> 16) & 0xFF);                                \
    (buf)[2] = (uint8_t)(((val) >> 8) & 0xFF);                                 \
    (buf)[3] = (uint8_t)((val) & 0xFF);                                        \
  } while (0)

#define READ_U16_BE(buf) (uint16_t)((((uint16_t)(buf)[0]) << 8) | (buf)[1])

#define READ_U32_BE(buf)                                                       \
  (uint32_t)((((uint32_t)(buf)[0]) << 24) | (((uint32_t)(buf)[1]) << 16) |     \
             (((uint32_t)(buf)[2]) << 8) | ((uint32_t)(buf)[3]))

/* -------------------------------------------------------------------------- */
/*                              UI YARDIMCILARI                               */
/* -------------------------------------------------------------------------- */

/* Durum mesajlarını statusQueueHandle'a gönderir */
static void send_status_ui(const char *m) {
  StatusMsg s;
  memset(&s, 0, sizeof(s));
  strncpy(s.text, m, sizeof(s.text) - 1);
  if (statusQueueHandle != NULL)
    osMessageQueuePut(statusQueueHandle, &s, 0, 0);
}

/* EPC verisini antenna ID ve RSSI ile epcQueueHandle'a gönderir */
static void send_epc_with_ant(const uint8_t *epc, uint8_t len, uint8_t antId,
                              int8_t rssi, uint16_t phase) {
  EpcData d;
  uint8_t i;
  uint8_t max_bytes = (len > 24) ? 24 : len;

  memset(&d, 0, sizeof(d));
  strcpy(d.hexString, "EPC:");
  for (i = 0; i < max_bytes; i++)
    snprintf(&d.hexString[4 + (i * 2)], 3, "%02X", epc[i]);

  d.antennaId = antId;
  d.peakRssi = rssi;
  d.phaseAngle = phase;

  if (epcQueueHandle != NULL)
    osMessageQueuePut(epcQueueHandle, &d, 0, 0);
}

/* -------------------------------------------------------------------------- */
/*                         LLRP HEADER / FRAME BUILD                          */
/* -------------------------------------------------------------------------- */

static void write_msg_header(uint8_t *buf, uint16_t type, uint32_t length,
                             uint32_t id) {
  /* version=1 → bits[12:10]=001, typeNum→bits[9:0] */
  WRITE_U16_BE(buf, (uint16_t)((1U << 10) | (type & 0x03FFU)));
  WRITE_U32_BE(buf + 2, length);
  WRITE_U32_BE(buf + 6, id);
}

static void write_tlv_header(uint8_t *buf, uint16_t type, uint16_t length) {
  /* TLV: top 2 bit = 00, sonra 14 bit typeNum */
  WRITE_U16_BE(buf, (uint16_t)(type & 0x3FFFU));
  WRITE_U16_BE(buf + 2, length);
}

/* -------------------------------------------------------------------------
 * ADD_ROSPEC — 91 byte
 *
 * Offset  Size  İçerik
 * ------  ----  -------
 *  0       10   Message header (type=20, len=91, id)
 * 10        4   ROSpec TLV header (177, 81)
 * 14        4   ROSpecID
 * 18        1   Priority = 0
 * 19        1   CurrentState = 0  ← KRİTİK, mutlaka 0
 * 20        4   ROBoundarySpec TLV header (178, 18)
 * 24        4   ROSpecStartTrigger TLV header (179, 5)
 * 28        1   StartTriggerType = 0 (Null)
 * 29        4   ROSpecStopTrigger TLV header (182, 9)
 * 33        1   StopTriggerType = 0 (Null)
 * 34        4   DurationTriggerValue = 0
 * 38        4   AISpec TLV header (183, 24)
 * 42        2   AntennaCount = 1  (u16v: önce count)
 * 44        2   AntennaID[0] = 0  (0 = tüm antenler)
 * 46        4   AISpecStopTrigger TLV header (184, 9)
 * 50        1   AIStopTriggerType = 0 (Null)
 * 51        4   DurationTrigger = 0
 * 55        4   InventoryParameterSpec TLV header (186, 7)
 * 59        2   InventoryParameterSpecID = 1
 * 61        1   ProtocolID = 1 (C1G2)
 * 62        4   ROReportSpec TLV header (237, 29)
 * 66        1   ROReportTrigger = 2 (End_Of_ROSpec)
 * 67        2   N = 0
 * 69        4   TagReportContentSelector TLV header(238,22)
 * 73        2   Selector bits = 0x1400 (EnableAntennaID | EnablePeakRSSI)
 * ------
 * Toplam: 75 byte
 * ------------------------------------------------------------------------- */
static int build_add_rospec(uint8_t *frame, uint32_t msg_id,
                            uint32_t rospec_id) {
  /* --- Message header --- */
  write_msg_header(frame, LLRP_MSG_ADD_ROSPEC, 75, msg_id);

  /* --- ROSpec TLV @10, len=65 --- */
  write_tlv_header(frame + 10, LLRP_PARAM_ROSPEC, 65);
  WRITE_U32_BE(frame + 14, rospec_id);
  WRITE_U8(frame + 18, 0x00);
  WRITE_U8(frame + 19, 0x00);

  /* --- ROBoundarySpec @20, len=18 --- */
  write_tlv_header(frame + 20, LLRP_PARAM_ROBOUNDARYSPEC, 18);

  /* ROSpecStartTrigger @24, len=5 */
  write_tlv_header(frame + 24, LLRP_PARAM_ROSPECSTARTTRIGGER, 5);
  WRITE_U8(frame + 28, 0x00);

  /* ROSpecStopTrigger @29, len=9 */
  write_tlv_header(frame + 29, LLRP_PARAM_ROSPECSTOPTRIGGER, 9);
  WRITE_U8(frame + 33, 0x00);
  WRITE_U32_BE(frame + 34, 0x00000000);

  /* --- AISpec @38, len=24 --- */
  write_tlv_header(frame + 38, LLRP_PARAM_AISPEC, 24);
  WRITE_U16_BE(frame + 42, 0x0001);
  WRITE_U16_BE(frame + 44, 0x0000);

  /* AISpecStopTrigger @46, len=9 */
  write_tlv_header(frame + 46, LLRP_PARAM_AISPECSTOPTRIGGER, 9);
  WRITE_U8(frame + 50, 0x00);
  WRITE_U32_BE(frame + 51, 0x00000000);

  /* InventoryParameterSpec @55, len=7 */
  write_tlv_header(frame + 55, LLRP_PARAM_INVENTORYPARAMETERSPEC, 7);
  WRITE_U16_BE(frame + 59, 0x0001);
  WRITE_U8(frame + 61, 0x01);

  /* --- ROReportSpec @62, len=13 --- */
  write_tlv_header(frame + 62, LLRP_PARAM_ROREPORTSPEC, 13);
  WRITE_U8(frame + 66, 0x01);       /* Upon_N_Tags_Or_End_Of_ROSpec */
  WRITE_U16_BE(frame + 67, 0x0001); /* N=1 */

  /* TagReportContentSelector @69, len=6 */
  write_tlv_header(frame + 69, LLRP_PARAM_TAGREPORTCONTENTSELECTOR, 6);
  WRITE_U16_BE(frame + 73, 0x1400); /* EnableAntennaID | EnablePeakRSSI */

  return 75;
}

/* -------------------------------------------------------------------------
 * SET_READER_CONFIG — Impinj Phase Angle etkinleştirme
 *
 * Offset  Size  İçerik
 * ------  ----  -------
 *  0       10   Message header (type=9, len=37, id)
 * 10        1   ResetToFactoryDefault = 0
 * 11        4   Custom TLV (1023, 26) ImpinjTagReportContentSelector
 * 15        4   VendorID = 25882
 * 19        4   Subtype = 50
 * 23        4   Custom TLV (1023, 14) ImpinjEnableRFPhaseAngle
 * 27        4   VendorID = 25882
 * 31        4   Subtype = 52
 * 35        2   RFPhaseAngleMode = 1 (Enabled)
 * ------
 * Toplam: 37 byte
 * ------------------------------------------------------------------------- */
static int build_set_reader_config_phase(uint8_t *frame, uint32_t msg_id) {
  write_msg_header(frame, LLRP_MSG_SET_READER_CONFIG, 37, msg_id);
  WRITE_U8(frame + 10, 0x00); /* ResetToFactoryDefault = 0 */

  /* ImpinjTagReportContentSelector @11, len=26 */
  write_tlv_header(frame + 11, 1023, 26);
  WRITE_U32_BE(frame + 15, 25882); /* Impinj VendorID */
  WRITE_U32_BE(frame + 19, 50);    /* Subtype=50 */

  /* ImpinjEnableRFPhaseAngle @23, len=14 */
  write_tlv_header(frame + 23, 1023, 14);
  WRITE_U32_BE(frame + 27, 25882);  /* Impinj VendorID */
  WRITE_U32_BE(frame + 31, 52);     /* Subtype=52 */
  WRITE_U16_BE(frame + 35, 0x0001); /* RFPhaseAngleMode = Enabled */

  return 37;
}

/* DELETE_ROSPEC — 14 byte (ROSpecID=0 → tümünü sil) */
static int build_delete_rospec(uint8_t *frame, uint32_t msg_id,
                               uint32_t rospec_id) {
  write_msg_header(frame, LLRP_MSG_DELETE_ROSPEC, 14, msg_id);
  WRITE_U32_BE(frame + 10, rospec_id); /* 0 = tüm ROSpec'leri sil */
  return 14;
}

/* ENABLE_ROSPEC — 14 byte */
static int build_enable_rospec(uint8_t *frame, uint32_t msg_id,
                               uint32_t rospec_id) {
  write_msg_header(frame, LLRP_MSG_ENABLE_ROSPEC, 14, msg_id);
  WRITE_U32_BE(frame + 10, rospec_id);
  return 14;
}

/* START_ROSPEC — 14 byte */
static int build_start_rospec(uint8_t *frame, uint32_t msg_id,
                              uint32_t rospec_id) {
  write_msg_header(frame, LLRP_MSG_START_ROSPEC, 14, msg_id);
  WRITE_U32_BE(frame + 10, rospec_id);
  return 14;
}

/* KEEPALIVE_ACK — 10 byte */
static int build_keepalive_ack(uint8_t *frame, uint32_t msg_id) {
  write_msg_header(frame, LLRP_MSG_KEEPALIVE_ACK, 10, msg_id);
  return 10;
}

/* -------------------------------------------------------------------------- */
/*                            SOCKET YARDIMCILARI                             */
/* -------------------------------------------------------------------------- */

static int wait_socket_readable(int sock, int timeout_ms) {
  fd_set readfds;
  struct timeval tv;
  int ret;

  FD_ZERO(&readfds);
  FD_SET(sock, &readfds);
  tv.tv_sec = timeout_ms / 1000;
  tv.tv_usec = (timeout_ms % 1000) * 1000;

  ret = select(sock + 1, &readfds, NULL, NULL, &tv);

  if (ret > 0 && FD_ISSET(sock, &readfds))
    return 1;
  if (ret == 0)
    return 0;
  return -1;
}

static int recv_exact_timeout(int sock, uint8_t *buf, int len, int timeout_ms) {
  int total = 0;
  int n;

  while (total < len) {
    int rdy = wait_socket_readable(sock, timeout_ms);
    if (rdy <= 0)
      return -1;

    n = recv(sock, (char *)(buf + total), len - total, 0);
    if (n <= 0)
      return -1;

    total += n;
  }
  return total;
}

/* Tam bir LLRP mesajını buffer'a alır. Dönen değer toplam byte sayısı veya
 * negatif hata. */
static int recv_llrp_message(int sock, uint8_t *buf, int buf_size) {
  int r;
  uint32_t total_len;

  if (buf_size < LLRP_HEADER_LEN)
    return -1;

  /* 1. Header al (g_recv_timeout_ms ile) */
  r = recv_exact_timeout(sock, buf, LLRP_HEADER_LEN, g_recv_timeout_ms);
  if (r != LLRP_HEADER_LEN)
    return -10;

  /* 2. Toplam uzunluk */
  total_len = READ_U32_BE(buf + 2);
  if (total_len < (uint32_t)LLRP_HEADER_LEN || total_len > (uint32_t)buf_size)
    return -11;

  /* 3. Kalan payload */
  if (total_len > (uint32_t)LLRP_HEADER_LEN) {
    r = recv_exact_timeout(sock, buf + LLRP_HEADER_LEN,
                           (int)(total_len - LLRP_HEADER_LEN),
                           g_recv_timeout_ms);
    if (r != (int)(total_len - LLRP_HEADER_LEN))
      return -12;
  }
  return (int)total_len;
}

static int send_all(int sock, const uint8_t *buf, int len) {
  int sent = 0;
  int n;

  while (sent < len) {
    n = send(sock, (const char *)(buf + sent), len - sent, 0);
    if (n <= 0)
      return -1;
    sent += n;
  }
  return 0;
}

/* -------------------------------------------------------------------------- */
/*                              LLRP PARSE                                    */
/* -------------------------------------------------------------------------- */

static uint16_t llrp_get_msg_type(const uint8_t *buf) {
  return (uint16_t)(READ_U16_BE(buf) & 0x03FFU);
}

static uint32_t llrp_get_msg_id(const uint8_t *buf) {
  return READ_U32_BE(buf + 6);
}

/* Response mesajlarındaki LLRPStatus.StatusCode'u döndürür (0=Başarı) */
static uint16_t llrp_get_status_code(const uint8_t *response_buf) {
  const uint8_t *ptr = response_buf + 10;
  uint16_t ptype = (uint16_t)(READ_U16_BE(ptr) & 0x3FFFU);

  if (ptype == LLRP_PARAM_LLRPSTATUS)
    return READ_U16_BE(ptr + 4);

  return 0xFFFFU; /* Parse hatası */
}

/*
 * TV format parametre boyları (header byte dahil):
 * TV header = 1 byte (bit7=1, bits[6:0]=typeNum)
 * Veri hemen arkasından gelir.
 */
static uint8_t tv_param_size(uint8_t typeNum) {
  switch (typeNum) {
  case 1:
    return 3; /* AntennaID: 1+2 */
  case 2:
    return 9; /* FirstSeenTimestampUTC: 1+8 */
  case 3:
    return 9; /* FirstSeenTimestampUptime: 1+8 */
  case 4:
    return 9; /* LastSeenTimestampUTC: 1+8 */
  case 5:
    return 9; /* LastSeenTimestampUptime: 1+8 */
  case 6:
    return 2; /* PeakRSSI: 1+1 */
  case 7:
    return 3; /* ChannelIndex: 1+2 */
  case 8:
    return 3; /* TagSeenCount: 1+2 */
  case 9:
    return 5; /* ROSpecID: 1+4 */
  case 10:
    return 3; /* InventoryParameterSpecID: 1+2 */
  case 13:
    return 13; /* EPC_96: 1+12 (96 bit = 12 byte) */
  case 14:
    return 3; /* SpecIndex: 1+2 */
  case 15:
    return 3; /* ClientRequestOpSpecResult: 1+2 */
  case 16:
    return 5; /* AccessSpecID: 1+4 */
  default:
    return 0; /* Bilinmiyor — çağıran çıkış yapmalı */
  }
}

/*
 * Tek bir TagReportData parametresinin içini parse eder.
 * İçinde EPCParameter bulursa send_epc_hex() çağırır.
 *
 * TagReportData yapısı:
 *   EPCParameter (choice, repeat=1): EPC_96 [TV,13] veya EPCData [TLV,241]
 *   Opsiyonel TV parametreler: AntennaID, PeakRSSI, vb.
 */
/*
 * TagReportData parse: AntennaID (TV type=1) ve EPC'yi birlikte çıkarır.
 * Tam bir pass yapar, sonra send_epc_with_ant() çağırır.
 */
static void parse_tag_report_data(const uint8_t *data, uint32_t len) {
  const uint8_t *ptr = data;
  const uint8_t *end = data + len;
  uint8_t antenna_id = 0;
  int8_t peak_rssi = 0;
  uint8_t epc_buf[24];
  uint8_t epc_len = 0;
  uint8_t has_epc = 0;
  uint16_t phase_angle = 0;

  while (ptr < end) {
    if (*ptr & 0x80U) {
      uint8_t tv_type = (uint8_t)(*ptr & 0x7FU);

      if (tv_type == 1) /* AntennaID: 1+2=3 byte */
      {
        if ((ptr + 3) <= end)
          antenna_id = (uint8_t)(READ_U16_BE(ptr + 1) & 0xFF);
        ptr += 3;
      } else if (tv_type == 6) /* PeakRSSI: 1+1=2 byte */
      {
        if ((ptr + 2) <= end)
          peak_rssi = (int8_t)(ptr[1]);
        ptr += 2;
      } else if (tv_type == LLRP_TV_EPC_96) /* EPC_96: 1+12=13 byte */
      {
        if ((ptr + 13) <= end && !has_epc) {
          memcpy(epc_buf, ptr + 1, 12);
          epc_len = 12;
          has_epc = 1;
        }
        ptr += 13;
      } else {
        uint8_t sz = tv_param_size(tv_type);
        if (sz == 0 || (ptr + sz) > end)
          break;
        ptr += sz;
      }
    } else {
      if ((ptr + 4) > end)
        break;
      uint16_t tlv_type = (uint16_t)(READ_U16_BE(ptr) & 0x3FFFU);
      uint16_t tlv_len = READ_U16_BE(ptr + 2);
      if (tlv_len < 4 || (ptr + tlv_len) > end)
        break;

      if (tlv_type == LLRP_PARAM_EPCDATA && !has_epc) {
        if (tlv_len >= 6) {
          uint16_t bit_count = READ_U16_BE(ptr + 4);
          uint8_t byte_count = (uint8_t)((bit_count + 7U) / 8U);
          if (byte_count > 24)
            byte_count = 24;
          if ((uint16_t)(6 + byte_count) <= tlv_len) {
            memcpy(epc_buf, ptr + 6, byte_count);
            epc_len = byte_count;
            has_epc = 1;
          }
        }
      } else if (tlv_type == 1023) /* Custom Parameter */
      {
        if (tlv_len >= 12) {
          uint32_t vendor = READ_U32_BE(ptr + 4);
          uint32_t subtype = READ_U32_BE(ptr + 8);

          /* ImpinjRFPhaseAngle: vendor=25882, subtype=56 (SDK), len=14 */
          if (vendor == 25882 && subtype == 56 && tlv_len >= 14) {
            phase_angle = READ_U16_BE(ptr + 12);
          }
        }
      }

      ptr += tlv_len;
    }
  }

  if (has_epc)
    send_epc_with_ant(epc_buf, epc_len, antenna_id, peak_rssi, phase_angle);
}

/*
 * RO_ACCESS_REPORT mesajını parse eder.
 * Mesaj: [10 byte header] [TagReportData TLV...] [RFSurveyReportData TLV...]
 * [Custom...] Her TagReportData için parse_tag_report_data() çağırır.
 */
static void llrp_parse_ro_access_report(const uint8_t *buf, uint32_t len) {
  uint32_t msg_len;
  const uint8_t *ptr;
  const uint8_t *end;

  (void)len;

  msg_len = READ_U32_BE(buf + 2);
  if (msg_len < (uint32_t)LLRP_HEADER_LEN)
    return;

  ptr = buf + LLRP_HEADER_LEN;
  end = buf + msg_len;

  while (ptr < end) {
    uint16_t ptype;
    uint16_t plen;

    /* RO_ACCESS_REPORT yalnızca TLV parametreler içerir (top 2 bit = 00) */
    if ((*ptr & 0xC0U) != 0)
      break;

    if ((ptr + 4) > end)
      break;

    ptype = (uint16_t)(READ_U16_BE(ptr) & 0x3FFFU);
    plen = READ_U16_BE(ptr + 2);

    if (plen < 4 || (ptr + plen) > end)
      break;

    if (ptype == LLRP_PARAM_TAGREPORTDATA) {
      parse_tag_report_data(ptr + 4, (uint32_t)(plen - 4));
    }
    /* RFSurveyReportData (242) ve Custom (1023) şimdilik atlanır */

    ptr += plen;
  }
}

/* -------------------------------------------------------------------------- */
/*                      ASYNC MESAJLAR / RESPONSE BEKLEME                     */
/* -------------------------------------------------------------------------- */

/*
 * Asenkron gelen mesajları işler (KEEPALIVE, EVENT_NOTIFICATION,
 * RO_ACCESS_REPORT). İşlendiyse 1, tanınmayan mesajsa 0 döner.
 */
static int handle_async_message(int sock, const uint8_t *buf, int len) {
  uint16_t mt = llrp_get_msg_type(buf);

  (void)len;

  if (mt == LLRP_MSG_KEEPALIVE) {
    uint8_t ack[10];
    int ack_len = build_keepalive_ack(ack, llrp_get_msg_id(buf));
    if (send_all(sock, ack, ack_len) == 0)
      send_status_ui("KA_ACK");
    else
      send_status_ui("KA_ACK_ERR");
    return 1;
  }

  if (mt == LLRP_MSG_READER_EVENT_NOTIFICATION) {
    send_status_ui("EVENT");
    return 1;
  }

  if (mt == LLRP_MSG_RO_ACCESS_REPORT) {
    llrp_parse_ro_access_report(buf, (uint32_t)len);
    return 1;
  }

  return 0;
}

/*
 * Beklenen mesaj tipini alana kadar döngüde okur.
 * Asenkron mesajlar handle_async_message() ile işlenir.
 * Başarıda 0, hata/timeout'ta negatif değer döner.
 */
static int wait_for_message_type(int sock, uint16_t expected_type,
                                 const char *label) {
  while (1) {
    int len = recv_llrp_message(sock, rx_global, RX_BUF_SIZE);
    if (len <= 0) {
      char msg[64];
      snprintf(msg, sizeof(msg), "%s TMOUT:%d", label, len);
      send_status_ui(msg);
      return -1;
    }

    uint16_t mt = llrp_get_msg_type(rx_global);

    /* Asenkron mesaj mı? */
    if (handle_async_message(sock, rx_global, len))
      continue;

    /* Beklenen response mu? */
    if (mt == expected_type) {
      uint16_t status = llrp_get_status_code(rx_global);
      if (status == 0) {
        char ok[48];
        snprintf(ok, sizeof(ok), "%s OK", label);
        send_status_ui(ok);
        return 0;
      } else {
        char err[64];
        snprintf(err, sizeof(err), "%s ERR:%u", label, status);
        send_status_ui(err);
        return -2;
      }
    }

    if (mt == LLRP_MSG_ERROR_MESSAGE) {
      uint16_t status = llrp_get_status_code(rx_global);
      char err[64];
      snprintf(err, sizeof(err), "%s ERRMSG:%u", label, status);
      send_status_ui(err);
      return -3;
    }

    /* Beklenmeyen ama tanınmayan mesaj — logla, döngüye devam et */
    {
      char msg[64];
      snprintf(msg, sizeof(msg), "%s SKIP MT:%u", label, mt);
      send_status_ui(msg);
    }
  }
}

/* Bağlantı kurulduğunda reader'ın gönderdiği ilk EVENT_NOTIFICATION beklenir */
static int wait_initial_reader_event(int sock) {
  while (1) {
    int len = recv_llrp_message(sock, rx_global, RX_BUF_SIZE);
    if (len <= 0) {
      char msg[48];
      snprintf(msg, sizeof(msg), "EVT TMOUT:%d", len);
      send_status_ui(msg);
      return -1;
    }

    uint16_t mt = llrp_get_msg_type(rx_global);

    if (mt == LLRP_MSG_READER_EVENT_NOTIFICATION) {
      send_status_ui("BAGLANTI EVT OK");
      return 0;
    }

    /* Başka bir şey gelirse asenkron handler'a ver, döngüye devam */
    if (handle_async_message(sock, rx_global, len))
      continue;

    /* Tanınmayan mesaj — yine de devam et (strict olmayalım) */
    {
      char msg[48];
      snprintf(msg, sizeof(msg), "ILK MT:%u",
               (unsigned)llrp_get_msg_type(rx_global));
      send_status_ui(msg);
    }
  }
}

/* -------------------------------------------------------------------------- */
/*                           LLRP KOMUT GÖNDERME                              */
/* -------------------------------------------------------------------------- */

static int send_delete_rospec_and_wait(int sock, uint32_t rospec_id) {
  uint8_t frame[14];
  int flen = build_delete_rospec(frame, g_msg_id++, rospec_id);

  if (send_all(sock, frame, flen) < 0) {
    send_status_ui("DEL SEND ERR");
    return -1;
  }
  /* DELETE_ROSPEC_RESPONSE (31) beklenir */
  return wait_for_message_type(sock, LLRP_MSG_DELETE_ROSPEC_RESPONSE, "DEL_RO");
}

static int send_add_rospec_and_wait(int sock, uint32_t rospec_id) {
  uint8_t frame[75];
  int flen = build_add_rospec(frame, g_msg_id++, rospec_id);

  if (send_all(sock, frame, flen) < 0) {
    send_status_ui("ADD SEND ERR");
    return -1;
  }
  return wait_for_message_type(sock, LLRP_MSG_ADD_ROSPEC_RESPONSE, "ADD_RO");
}

static int send_enable_rospec_and_wait(int sock, uint32_t rospec_id) {
  uint8_t frame[14];
  int flen = build_enable_rospec(frame, g_msg_id++, rospec_id);

  if (send_all(sock, frame, flen) < 0) {
    send_status_ui("ENA SEND ERR");
    return -1;
  }
  return wait_for_message_type(sock, LLRP_MSG_ENABLE_ROSPEC_RESPONSE, "ENA_RO");
}

static int send_start_rospec_and_wait(int sock, uint32_t rospec_id) {
  uint8_t frame[14];
  int flen = build_start_rospec(frame, g_msg_id++, rospec_id);

  if (send_all(sock, frame, flen) < 0) {
    send_status_ui("STA SEND ERR");
    return -1;
  }
  return wait_for_message_type(sock, LLRP_MSG_START_ROSPEC_RESPONSE, "STA_RO");
}

/* -------------------------------------------------------------------------- */
/*                                ANA GÖREV                                   */
/* -------------------------------------------------------------------------- */

void StartLlrpTask(void *argument) {
  int s;
  struct sockaddr_in addr;
  uint8_t cmd;
  int consec_timeout;

  (void)argument;

  /* Kuyrukları oluştur */
  if (epcQueueHandle == NULL)
    epcQueueHandle = osMessageQueueNew(10, sizeof(EpcData), NULL);
  if (statusQueueHandle == NULL)
    statusQueueHandle = osMessageQueueNew(10, sizeof(StatusMsg), NULL);
  if (cmdQueueHandle == NULL)
    cmdQueueHandle = osMessageQueueNew(5, sizeof(uint8_t), NULL);

  osDelay(3000); /* lwIP başlamasını bekle */
  send_status_ui("HAZIR: BAGLAN TUSUNA BASIN");

  while (1) {
    /* --- BAGLAN komutunu bekle --- */
    cmd = 0;
    while (osMessageQueueGet(cmdQueueHandle, &cmd, NULL, osWaitForever) == osOK)
      if (cmd == LLRP_CMD_CONNECT)
        break;

    send_status_ui("BAGLANIYOR...");
    g_recv_timeout_ms = SOCKET_TIMEOUT_MS;

    /* TCP soket */
    s = socket(AF_INET, SOCK_STREAM, 0);
    if (s < 0) {
      send_status_ui("SOKET HATASI");
      osDelay(1000);
      send_status_ui("HAZIR: BAGLAN TUSUNA BASIN");
      continue;
    }

    memset(&addr, 0, sizeof(addr));
    addr.sin_family = AF_INET;
    addr.sin_port = htons((uint16_t)READER_PORT);
    addr.sin_addr.s_addr = inet_addr(READER_IP_ADDR);

    if (connect(s, (struct sockaddr *)&addr, sizeof(addr)) < 0) {
      closesocket(s);
      send_status_ui("BAGLANTI HATASI");
      osDelay(2000);
      send_status_ui("HAZIR: BAGLAN TUSUNA BASIN");
      continue;
    }
    send_status_ui("TCP BAGLANDI");

    if (wait_initial_reader_event(s) < 0)
      goto reconnect;

    if (send_delete_rospec_and_wait(s, 0) < 0)
      send_status_ui("DEL ATLANDI");

    /* Impinj Phase Angle etkinleştir (SET_READER_CONFIG) */
    {
      uint8_t cfgframe[37];
      int cfglen = build_set_reader_config_phase(cfgframe, g_msg_id++);
      if (send_all(s, cfgframe, cfglen) < 0) {
        send_status_ui("CFG SEND ERR");
        goto reconnect;
      }
      if (wait_for_message_type(s, LLRP_MSG_SET_READER_CONFIG_RESPONSE,
                                "CFG_PH") < 0)
        send_status_ui("CFG_PH ATLANDI"); /* Hata olsa bile devam et */
    }

    if (send_add_rospec_and_wait(s, 1) < 0)
      goto reconnect;
    if (send_enable_rospec_and_wait(s, 1) < 0)
      goto reconnect;

    send_status_ui("HAZIR: BASLAT TUSUNA BASIN");

    /* --- BASLAT veya DURDUR komutunu bekle --- */
    cmd = 0;
    while (1) {
      if (osMessageQueueGet(cmdQueueHandle, &cmd, NULL, 200) == osOK) {
        if (cmd == LLRP_CMD_START)
          break;
        if (cmd == LLRP_CMD_STOP)
          goto reconnect;
      }
    }

    if (send_start_rospec_and_wait(s, 1) < 0)
      goto reconnect;
    send_status_ui("OKUMA AKTIF");

    /* --- Ana dinleme döngüsü --- */
    g_recv_timeout_ms = LISTEN_TIMEOUT_MS;
    consec_timeout = 0;

    while (1) {
      /* DURDUR komutunu kontrol et (bloklamadan) */
      if (osMessageQueueGet(cmdQueueHandle, &cmd, NULL, 0) == osOK) {
        if (cmd == LLRP_CMD_STOP) {
          send_status_ui("DURDURULDU");
          goto reconnect;
        }
      }

      int len = recv_llrp_message(s, rx_global, RX_BUF_SIZE);
      if (len <= 0) {
        /* -10 = sadece timeout → komut kontrolüne dön */
        if (len == -10) {
          consec_timeout++;
        } else {
          consec_timeout += 5;
        }

        if (consec_timeout > 15) /* ~30 sn veri yok = ger­çek hata */
        {
          send_status_ui("BAGLANTI KOPTU");
          break;
        }
        continue;
      }
      consec_timeout = 0;

      {
        uint16_t mt = llrp_get_msg_type(rx_global);
        if (mt == LLRP_MSG_RO_ACCESS_REPORT)
          llrp_parse_ro_access_report(rx_global, (uint32_t)len);
        else if (mt == LLRP_MSG_KEEPALIVE) {
          uint8_t ack[10];
          int ack_len = build_keepalive_ack(ack, llrp_get_msg_id(rx_global));
          send_all(s, ack, ack_len);
        }
        /* READER_EVENT_NOTIFICATION: yoksay */
      }
      osDelay(1);
    }

  reconnect:
    closesocket(s);
    g_recv_timeout_ms = SOCKET_TIMEOUT_MS;
    send_status_ui("SOKET KAPANDI");
    osDelay(1000);
    send_status_ui("HAZIR: BAGLAN TUSUNA BASIN");
  }
}
